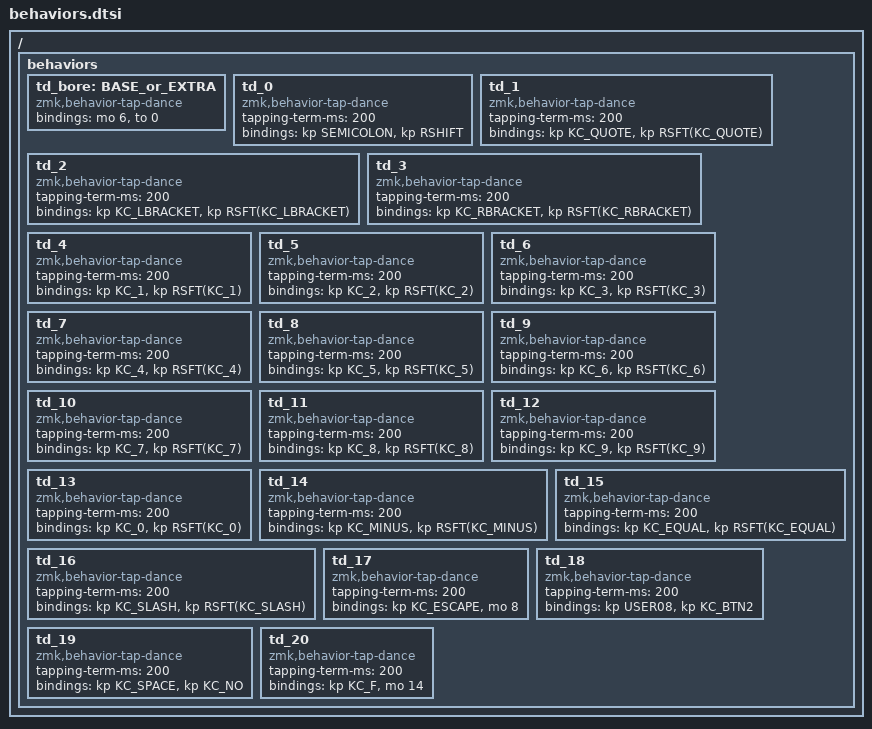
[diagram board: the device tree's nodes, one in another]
/ {
    behaviors {
        td_bore: BASE_or_EXTRA {
            compatible = "zmk,behavior-tap-dance";
            #binding-cells = <0>;
            bindings = <&mo 6>, <&to 0>;
        };

        td_0: td_0 {
            compatible = "zmk,behavior-tap-dance";
            #binding-cells = <0>;
            tapping-term-ms = <200>;
            bindings = <&kp SEMICOLON>, <&kp RSHIFT>;
        };
        td_1: td_1 {
            compatible = "zmk,behavior-tap-dance";
            #binding-cells = <0>;
            tapping-term-ms = <200>;
            bindings = <&kp KC_QUOTE>, <&kp RSFT(KC_QUOTE)>;
        };
        td_2: td_2 {
            compatible = "zmk,behavior-tap-dance";
            #binding-cells = <0>;
            tapping-term-ms = <200>;
            bindings = <&kp KC_LBRACKET>, <&kp RSFT(KC_LBRACKET)>;
        };
        td_3: td_3 {
            compatible = "zmk,behavior-tap-dance";
            #binding-cells = <0>;
            tapping-term-ms = <200>;
            bindings = <&kp KC_RBRACKET>, <&kp RSFT(KC_RBRACKET)>;
        };
        td_4: td_4 {
            compatible = "zmk,behavior-tap-dance";
            #binding-cells = <0>;
            tapping-term-ms = <200>;
            bindings = <&kp KC_1>, <&kp RSFT(KC_1)>;
        };
        td_5: td_5 {
            compatible = "zmk,behavior-tap-dance";
            #binding-cells = <0>;
            tapping-term-ms = <200>;
            bindings = <&kp KC_2>, <&kp RSFT(KC_2)>;
        };
        td_6: td_6 {
            compatible = "zmk,behavior-tap-dance";
            #binding-cells = <0>;
            tapping-term-ms = <200>;
            bindings = <&kp KC_3>, <&kp RSFT(KC_3)>;
        };
        td_7: td_7 {
            compatible = "zmk,behavior-tap-dance";
            #binding-cells = <0>;
            tapping-term-ms = <200>;
            bindings = <&kp KC_4>, <&kp RSFT(KC_4)>;
        };
        td_8: td_8 {
            compatible = "zmk,behavior-tap-dance";
            #binding-cells = <0>;
            tapping-term-ms = <200>;
            bindings = <&kp KC_5>, <&kp RSFT(KC_5)>;
        };
        td_9: td_9 {
            compatible = "zmk,behavior-tap-dance";
            #binding-cells = <0>;
            tapping-term-ms = <200>;
            bindings = <&kp KC_6>, <&kp RSFT(KC_6)>;
        };
        td_10: td_10 {
            compatible = "zmk,behavior-tap-dance";
            #binding-cells = <0>;
            tapping-term-ms = <200>;
            bindings = <&kp KC_7>, <&kp RSFT(KC_7)>;
        };
        td_11: td_11 {
            compatible = "zmk,behavior-tap-dance";
            #binding-cells = <0>;
            tapping-term-ms = <200>;
            bindings = <&kp KC_8>, <&kp RSFT(KC_8)>;
        };
        td_12: td_12 {
            compatible = "zmk,behavior-tap-dance";
            #binding-cells = <0>;
            tapping-term-ms = <200>;
            bindings = <&kp KC_9>, <&kp RSFT(KC_9)>;
        };
        td_13: td_13 {
            compatible = "zmk,behavior-tap-dance";
            #binding-cells = <0>;
            tapping-term-ms = <200>;
            bindings = <&kp KC_0>, <&kp RSFT(KC_0)>;
        };
        td_14: td_14 {
            compatible = "zmk,behavior-tap-dance";
            #binding-cells = <0>;
            tapping-term-ms = <200>;
            bindings = <&kp KC_MINUS>, <&kp RSFT(KC_MINUS)>;
        };
        td_15: td_15 {
            compatible = "zmk,behavior-tap-dance";
            #binding-cells = <0>;
            tapping-term-ms = <200>;
            bindings = <&kp KC_EQUAL>, <&kp RSFT(KC_EQUAL)>;
        };
        td_16: td_16 {
            compatible = "zmk,behavior-tap-dance";
            #binding-cells = <0>;
            tapping-term-ms = <200>;
            bindings = <&kp KC_SLASH>, <&kp RSFT(KC_SLASH)>;
        };
        td_17: td_17 {
            compatible = "zmk,behavior-tap-dance";
            #binding-cells = <0>;
            tapping-term-ms = <200>;
            bindings = <&kp KC_ESCAPE>, <&mo 8>;
        };
        td_18: td_18 {
            compatible = "zmk,behavior-tap-dance";
            #binding-cells = <0>;
            tapping-term-ms = <200>;
            bindings = <&kp USER08>, <&kp KC_BTN2>;
        };
        td_19: td_19 {
            compatible = "zmk,behavior-tap-dance";
            #binding-cells = <0>;
            tapping-term-ms = <200>;
            bindings = <&kp KC_SPACE>, <&kp KC_NO>;
        };
        td_20: td_20 {
            compatible = "zmk,behavior-tap-dance";
            #binding-cells = <0>;
            tapping-term-ms = <200>;
            bindings = <&kp KC_F>, <&mo 14>;
        };
    };
};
